VERSION ""

NS_ :

BS_:

BU_: INV BMS VCU

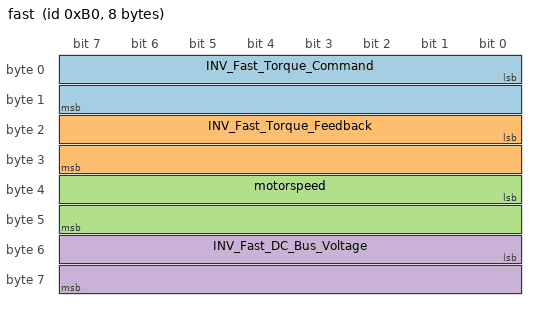
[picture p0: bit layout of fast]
BO_ 176 fast: 8 Vector__XXX
 SG_ INV_Fast_Torque_Command : 0|16@1- (0.1,0) [-3276.8|32767.7] "N.m" Vector__XXX
 SG_ INV_Fast_Torque_Feedback : 16|16@1- (0.1,0) [-3276.8|3276.7] "N.m" Vector__XXX
 SG_ motorspeed : 32|16@1- (1,0) [-32768|32767] "rpm" Vector__XXX
 SG_ INV_Fast_DC_Bus_Voltage : 48|16@1- (0.1,0) [-3276.8|3276.7] "V" Vector__XXX

CM_ BO_ 176 "To enable fast message set CAN ACTIVE MSGS HI WORD to 0xFFFE.  Setting to default value of 0xFFFF will disable the fast message.";
CM_ SG_ 176 INV_Fast_Torque_Command "The commanded torque";
CM_ SG_ 176 INV_Fast_Torque_Feedback "The estimated torque";
CM_ SG_ 176 motorspeed "Motor speed";
CM_ SG_ 176 INV_Fast_DC_Bus_Voltage "DC Bus Voltage";
BA_DEF_ BO_  "GenMsgCycleTime" INT 0 100000;
BA_DEF_  "BusType" STRING ;
BA_DEF_DEF_  "GenMsgCycleTime" 0;
BA_DEF_DEF_  "BusType" "CAN";
BA_ "GenMsgCycleTime" BO_ 176 3;
